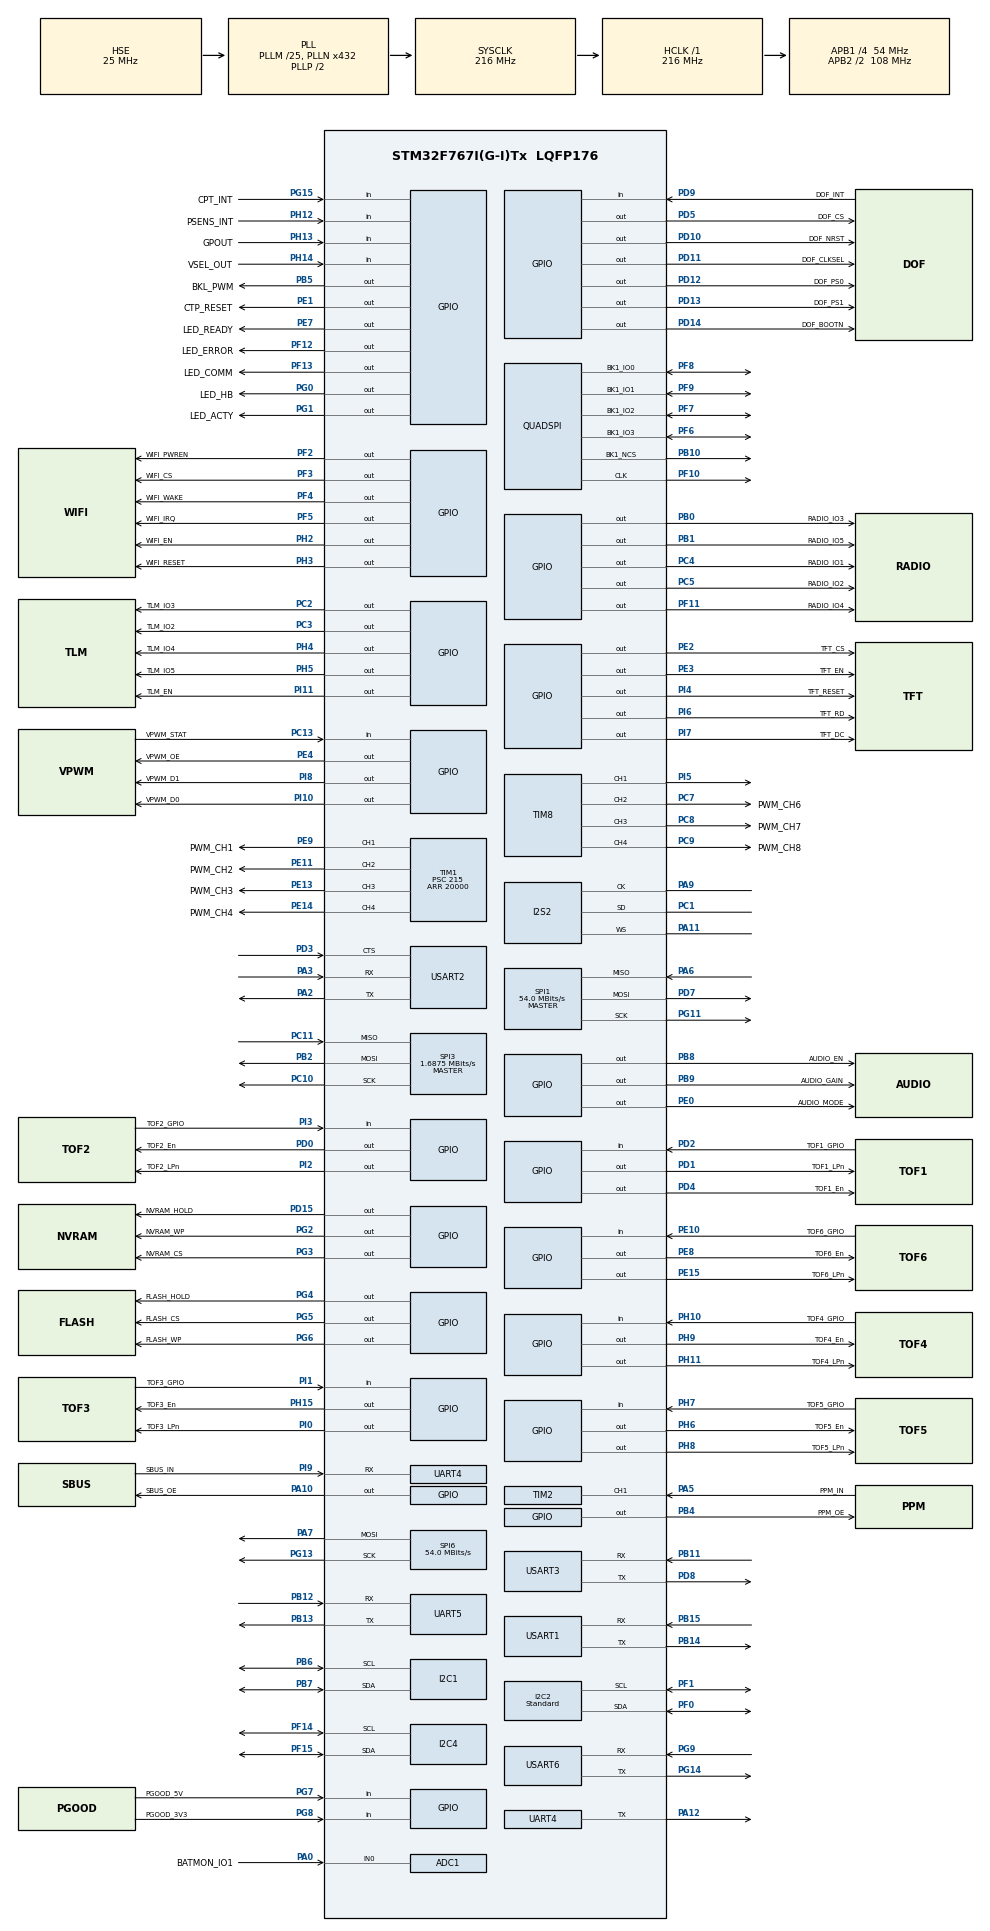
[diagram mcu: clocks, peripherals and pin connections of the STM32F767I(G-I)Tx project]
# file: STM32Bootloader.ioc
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ADC1.Channel-0\#ChannelRegularConversion=ADC_CHANNEL_0
ADC1.NbrOfConversionFlag=1
ADC1.Rank-0\#ChannelRegularConversion=1
ADC1.SamplingTime-0\#ChannelRegularConversion=ADC_SAMPLETIME_3CYCLES
ADC1.master=1
CORTEX_M7.AccessPermission-Cortex_Memory_Protection_Unit_Region0_Settings=MPU_REGION_FULL_ACCESS
CORTEX_M7.AccessPermission-Cortex_Memory_Protection_Unit_Region2_Settings=MPU_REGION_FULL_ACCESS
CORTEX_M7.AccessPermission-Cortex_Memory_Protection_Unit_Region3_Settings=MPU_REGION_FULL_ACCESS
CORTEX_M7.AccessPermission_S-Cortex_Memory_Protection_Unit_Region2_Settings_S=MPU_REGION_FULL_ACCESS
CORTEX_M7.AccessPermission_S-Cortex_Memory_Protection_Unit_Region3_Settings_S=MPU_REGION_FULL_ACCESS
CORTEX_M7.BaseAddress-Cortex_Memory_Protection_Unit_Region0_Settings=0x20000000
CORTEX_M7.BaseAddress-Cortex_Memory_Protection_Unit_Region1_Settings=0x90000000
CORTEX_M7.BaseAddress-Cortex_Memory_Protection_Unit_Region2_Settings=0x90000000
CORTEX_M7.BaseAddress-Cortex_Memory_Protection_Unit_Region3_Settings=0x90000000
CORTEX_M7.BaseAddress_S-Cortex_Memory_Protection_Unit_Region1_Settings_S=0x90000000
CORTEX_M7.BaseAddress_S-Cortex_Memory_Protection_Unit_Region2_Settings_S=0x90000000
CORTEX_M7.BaseAddress_S-Cortex_Memory_Protection_Unit_Region3_Settings_S=0x90000000
CORTEX_M7.BaseAddress_Spec=0x20000000
CORTEX_M7.CPU_DCache=Enabled
CORTEX_M7.CPU_ICache=Enabled
CORTEX_M7.DisableExec-Cortex_Memory_Protection_Unit_Region0_Settings=MPU_INSTRUCTION_ACCESS_DISABLE
CORTEX_M7.DisableExec-Cortex_Memory_Protection_Unit_Region1_Settings=MPU_INSTRUCTION_ACCESS_DISABLE
CORTEX_M7.DisableExec_S-Cortex_Memory_Protection_Unit_Region1_Settings_S=MPU_INSTRUCTION_ACCESS_DISABLE
CORTEX_M7.Enable-Cortex_Memory_Protection_Unit_Region0_Settings=MPU_REGION_ENABLE
CORTEX_M7.Enable-Cortex_Memory_Protection_Unit_Region1_Settings=MPU_REGION_ENABLE
CORTEX_M7.Enable-Cortex_Memory_Protection_Unit_Region2_Settings=MPU_REGION_ENABLE
CORTEX_M7.Enable-Cortex_Memory_Protection_Unit_Region3_Settings=MPU_REGION_ENABLE
CORTEX_M7.Enable_S-Cortex_Memory_Protection_Unit_Region1_Settings_S=MPU_REGION_ENABLE
CORTEX_M7.Enable_S-Cortex_Memory_Protection_Unit_Region2_Settings_S=MPU_REGION_ENABLE
CORTEX_M7.Enable_S-Cortex_Memory_Protection_Unit_Region3_Settings_S=MPU_REGION_ENABLE
CORTEX_M7.IsBufferable-Cortex_Memory_Protection_Unit_Region3_Settings=MPU_ACCESS_BUFFERABLE
CORTEX_M7.IsBufferable_S-Cortex_Memory_Protection_Unit_Region3_Settings_S=MPU_ACCESS_BUFFERABLE
CORTEX_M7.IsCacheable-Cortex_Memory_Protection_Unit_Region2_Settings=MPU_ACCESS_CACHEABLE
CORTEX_M7.IsCacheable-Cortex_Memory_Protection_Unit_Region3_Settings=MPU_ACCESS_CACHEABLE
CORTEX_M7.IsCacheable_S-Cortex_Memory_Protection_Unit_Region2_Settings_S=MPU_ACCESS_CACHEABLE
CORTEX_M7.IsCacheable_S-Cortex_Memory_Protection_Unit_Region3_Settings_S=MPU_ACCESS_CACHEABLE
CORTEX_M7.IsShareable-Cortex_Memory_Protection_Unit_Region0_Settings=MPU_ACCESS_SHAREABLE
CORTEX_M7.MPU_Control=MPU_PRIVILEGED_DEFAULT
CORTEX_M7.PREFETCH_ENABLE=1
CORTEX_M7.Size-Cortex_Memory_Protection_Unit_Region0_Settings=MPU_REGION_SIZE_512MB
CORTEX_M7.Size-Cortex_Memory_Protection_Unit_Region1_Settings=MPU_REGION_SIZE_512MB
CORTEX_M7.Size-Cortex_Memory_Protection_Unit_Region2_Settings=MPU_REGION_SIZE_16MB
CORTEX_M7.Size-Cortex_Memory_Protection_Unit_Region3_Settings=MPU_REGION_SIZE_1MB
CORTEX_M7.Size_S-Cortex_Memory_Protection_Unit_Region1_Settings_S=MPU_REGION_SIZE_512MB
CORTEX_M7.Size_S-Cortex_Memory_Protection_Unit_Region2_Settings_S=MPU_REGION_SIZE_16MB
CORTEX_M7.Size_S-Cortex_Memory_Protection_Unit_Region3_Settings_S=MPU_REGION_SIZE_1MB
CORTEX_M7.Size_Spec=MPU_REGION_SIZE_512KB
CORTEX_M7.SubRegionDisable_Spec=0x0
CORTEX_M7.TypeExtField-Cortex_Memory_Protection_Unit_Region0_Settings=MPU_TEX_LEVEL1
CORTEX_M7.default_mode_Activation=0
Dma.QUADSPI.0.Direction=DMA_PERIPH_TO_MEMORY
Dma.QUADSPI.0.FIFOMode=DMA_FIFOMODE_DISABLE
Dma.QUADSPI.0.Instance=DMA2_Stream2
Dma.QUADSPI.0.MemDataAlignment=DMA_MDATAALIGN_BYTE
Dma.QUADSPI.0.MemInc=DMA_MINC_ENABLE
Dma.QUADSPI.0.Mode=DMA_NORMAL
Dma.QUADSPI.0.PeriphDataAlignment=DMA_PDATAALIGN_BYTE
Dma.QUADSPI.0.PeriphInc=DMA_PINC_DISABLE
Dma.QUADSPI.0.Priority=DMA_PRIORITY_LOW
Dma.Request0=QUADSPI
Dma.Request1=USART1_RX
Dma.Request2=USART1_TX
Dma.USART1_RX.1.Direction=DMA_PERIPH_TO_MEMORY
Dma.USART1_RX.1.FIFOMode=DMA_FIFOMODE_DISABLE
Dma.USART1_RX.1.Instance=DMA2_Stream5
Dma.USART1_RX.1.MemDataAlignment=DMA_MDATAALIGN_BYTE
Dma.USART1_RX.1.MemInc=DMA_MINC_ENABLE
Dma.USART1_RX.1.Mode=DMA_CIRCULAR
Dma.USART1_RX.1.PeriphDataAlignment=DMA_PDATAALIGN_BYTE
Dma.USART1_RX.1.PeriphInc=DMA_PINC_DISABLE
Dma.USART1_RX.1.Priority=DMA_PRIORITY_LOW
Dma.USART1_TX.2.Direction=DMA_MEMORY_TO_PERIPH
Dma.USART1_TX.2.FIFOMode=DMA_FIFOMODE_DISABLE
Dma.USART1_TX.2.Instance=DMA2_Stream7
Dma.USART1_TX.2.MemDataAlignment=DMA_MDATAALIGN_BYTE
Dma.USART1_TX.2.MemInc=DMA_MINC_ENABLE
Dma.USART1_TX.2.Mode=DMA_NORMAL
Dma.USART1_TX.2.PeriphDataAlignment=DMA_PDATAALIGN_BYTE
Dma.USART1_TX.2.PeriphInc=DMA_PINC_DISABLE
Dma.USART1_TX.2.Priority=DMA_PRIORITY_LOW
FREERTOS.Tasks01=defaultTask,24,128,StartDefaultTask,Default,NULL,Dynamic,NULL,NULL
FREERTOS.configTOTAL_HEAP_SIZE=60000
I2C1.Timing=0x20404768
I2C2.I2C_Speed_Mode=I2C_Standard
I2C2.Timing=0x20404768
I2C4.Timing=0x20404768
I2S2.ErrorAudioFreq=0.0 %
I2S2.FullDuplexMode=I2S_FULLDUPLEXMODE_DISABLE
I2S2.Instance=SPI$Index
I2S2.RealAudioFreq=8.0 KHz
I2S2.VirtualMode=I2S_MODE_MASTER
Mcu.Family=STM32F7
Mcu.Name=STM32F767I(G-I)Tx
Mcu.Package=LQFP176
NVIC.DMA2_Stream2_IRQn=true\:5\:0\:false\:false\:true\:true\:false\:true\:true
NVIC.DMA2_Stream5_IRQn=true\:5\:0\:false\:false\:true\:false\:false\:true\:true
NVIC.DMA2_Stream7_IRQn=true\:5\:0\:false\:false\:true\:true\:false\:true\:true
NVIC.PriorityGroup=NVIC_PRIORITYGROUP_4
NVIC.QUADSPI_IRQn=true\:5\:0\:false\:false\:true\:true\:true\:true\:true
NVIC.TIM6_DAC_IRQn=true\:15\:0\:false\:false\:true\:false\:false\:true\:true
NVIC.TimeBase=TIM6_DAC_IRQn
NVIC.TimeBaseIP=TIM6
NVIC.USART1_IRQn=true\:5\:0\:false\:false\:true\:true\:true\:true\:true
PA0/WKUP.GPIO_Label=BATMON_IO1
PA0/WKUP.Signal=ADCx_IN0
PA10.GPIO_Label=SBUS_OE
PA10.Signal=GPIO_Output
PA11.Mode=Half_Duplex_Master
PA11.Signal=I2S2_WS
PA12.Mode=Asynchronous
PA12.Signal=UART4_TX
PA2.Mode=Asynchronous
PA2.Signal=USART2_TX
PA3.Mode=Asynchronous
PA3.Signal=USART2_RX
PA5.GPIO_Label=PPM_IN
PA5.Signal=S_TIM2_CH1_ETR
PA6.Mode=Full_Duplex_Master
PA6.Signal=SPI1_MISO
PA7.Mode=TX_Only_Simplex_Unidirect_Master
PA7.Signal=SPI6_MOSI
PA9.Mode=Half_Duplex_Master
PA9.Signal=I2S2_CK
PB0.GPIO_Label=RADIO_IO3
PB0.Signal=GPIO_Output
PB1.GPIO_Label=RADIO_IO5
PB1.Signal=GPIO_Output
PB10.GPIO_PuPd=GPIO_PULLDOWN
PB10.Mode=Single Bank 1
PB10.Signal=QUADSPI_BK1_NCS
PB11.Mode=Asynchronous
PB11.Signal=USART3_RX
PB12.Mode=Asynchronous
PB12.Signal=UART5_RX
PB13.Mode=Asynchronous
PB13.Signal=UART5_TX
PB14.Mode=Asynchronous
PB14.Signal=USART1_TX
PB15.Mode=Asynchronous
PB15.Signal=USART1_RX
PB2.Mode=Full_Duplex_Master
PB2.Signal=SPI3_MOSI
PB4.GPIO_Label=PPM_OE
PB4.Signal=GPIO_Output
PB5.GPIO_Label=BKL_PWM
PB5.Signal=GPIO_Output
PB6.Mode=I2C
PB6.Signal=I2C1_SCL
PB7.Mode=I2C
PB7.Signal=I2C1_SDA
PB8.GPIO_Label=AUDIO_EN
PB8.Signal=GPIO_Output
PB9.GPIO_Label=AUDIO_GAIN
PB9.Signal=GPIO_Output
PC1.Mode=Half_Duplex_Master
PC1.Signal=I2S2_SD
PC10.Mode=Full_Duplex_Master
PC10.Signal=SPI3_SCK
PC11.Mode=Full_Duplex_Master
PC11.Signal=SPI3_MISO
PC13.GPIO_Label=VPWM_STAT
PC13.Signal=GPIO_Input
PC14/OSC32_IN.Mode=LSE-External-Oscillator
PC14/OSC32_IN.Signal=RCC_OSC32_IN
PC15/OSC32_OUT.Mode=LSE-External-Oscillator
PC15/OSC32_OUT.Signal=RCC_OSC32_OUT
PC2.GPIO_Label=TLM_IO3
PC2.Signal=GPIO_Output
PC3.GPIO_Label=TLM_IO2
PC3.Signal=GPIO_Output
PC4.GPIO_Label=RADIO_IO1
PC4.Signal=GPIO_Output
PC5.GPIO_Label=RADIO_IO2
PC5.Signal=GPIO_Output
PC7.GPIO_Label=PWM_CH6
PC7.Signal=S_TIM8_CH2
PC8.GPIO_Label=PWM_CH7
PC8.Signal=S_TIM8_CH3
PC9.GPIO_Label=PWM_CH8
PC9.Signal=S_TIM8_CH4
PD0.GPIO_Label=TOF2_En
PD0.Signal=GPIO_Output
PD1.GPIO_Label=TOF1_LPn
PD1.Signal=GPIO_Output
PD10.GPIO_Label=DOF_NRST
PD10.GPIO_PuPd=GPIO_PULLUP
PD10.PinState=GPIO_PIN_SET
PD10.Signal=GPIO_Output
PD11.GPIO_Label=DOF_CLKSEL
PD11.GPIO_PuPd=GPIO_PULLDOWN
PD11.PinState=GPIO_PIN_RESET
PD11.Signal=GPIO_Output
PD12.GPIO_Label=DOF_PS0
PD12.GPIO_PuPd=GPIO_PULLUP
PD12.PinState=GPIO_PIN_SET
PD12.Signal=GPIO_Output
PD13.GPIO_Label=DOF_PS1
PD13.GPIO_PuPd=GPIO_PULLUP
PD13.PinState=GPIO_PIN_SET
PD13.Signal=GPIO_Output
PD14.GPIO_Label=DOF_BOOTN
PD14.GPIO_PuPd=GPIO_PULLUP
PD14.PinState=GPIO_PIN_SET
PD14.Signal=GPIO_Output
PD15.GPIO_Label=NVRAM_HOLD
PD15.GPIO_PuPd=GPIO_NOPULL
PD15.Signal=GPIO_Output
PD2.GPIO_Label=TOF1_GPIO
PD2.Signal=GPIO_Input
PD3.Mode=CTS_Only
PD3.Signal=USART2_CTS
PD4.GPIO_Label=TOF1_En 
PD4.Signal=GPIO_Output
PD5.GPIO_Label=DOF_CS
PD5.GPIO_PuPd=GPIO_PULLUP
PD5.PinState=GPIO_PIN_SET
PD5.Signal=GPIO_Output
PD7.Mode=Full_Duplex_Master
PD7.Signal=SPI1_MOSI
PD8.Mode=Asynchronous
PD8.Signal=USART3_TX
PD9.GPIO_Label=DOF_INT
PD9.GPIO_PuPd=GPIO_PULLUP
PD9.Signal=GPIO_Input
PE0.GPIO_Label=AUDIO_MODE
PE0.Signal=GPIO_Output
PE1.GPIO_Label=CTP_RESET
PE1.Signal=GPIO_Output
PE10.GPIO_Label=TOF6_GPIO
PE10.Signal=GPIO_Input
PE11.GPIO_Label=PWM_CH2
PE11.Signal=S_TIM1_CH2
PE13.GPIO_Label=PWM_CH3
PE13.Signal=S_TIM1_CH3
PE14.GPIO_Label=PWM_CH4
PE14.Signal=S_TIM1_CH4
PE15.GPIO_Label=TOF6_LPn
PE15.Signal=GPIO_Output
PE2.GPIO_Label=TFT_CS
PE2.GPIO_PuPd=GPIO_PULLUP
PE2.Signal=GPIO_Output
PE3.GPIO_Label=TFT_EN
PE3.Signal=GPIO_Output
PE4.GPIO_Label=VPWM_OE
PE4.Signal=GPIO_Output
PE7.GPIO_Label=LED_READY
PE7.PinState=GPIO_PIN_SET
PE7.Signal=GPIO_Output
PE8.GPIO_Label=TOF6_En
PE8.Signal=GPIO_Output
PE9.GPIO_Label=PWM_CH1
PE9.Signal=S_TIM1_CH1
PF0.GPIO_Pu=GPIO_PULLUP
PF0.Mode=I2C
PF0.Signal=I2C2_SDA
PF1.GPIO_Pu=GPIO_PULLUP
PF1.Mode=I2C
PF1.Signal=I2C2_SCL
PF10.GPIO_PuPd=GPIO_NOPULL
PF10.Mode=Single Bank 1
PF10.Signal=QUADSPI_CLK
PF11.GPIO_Label=RADIO_IO4
PF11.Signal=GPIO_Output
PF12.GPIO_Label=LED_ERROR
PF12.PinState=GPIO_PIN_SET
PF12.Signal=GPIO_Output
PF13.GPIO_Label=LED_COMM
PF13.PinState=GPIO_PIN_SET
PF13.Signal=GPIO_Output
PF14.Mode=I2C
PF14.Signal=I2C4_SCL
PF15.Mode=I2C
PF15.Signal=I2C4_SDA
PF2.GPIO_Label=WIFI_PWREN
PF2.Signal=GPIO_Output
PF3.GPIO_Label=WIFI_CS
PF3.GPIO_PuPd=GPIO_PULLUP
PF3.Signal=GPIO_Output
PF4.GPIO_Label=WIFI_WAKE
PF4.Signal=GPIO_Output
PF5.GPIO_Label=WIFI_IRQ
PF5.Signal=GPIO_Output
PF6.Mode=Single Bank 1
PF6.Signal=QUADSPI_BK1_IO3
PF7.Mode=Single Bank 1
PF7.Signal=QUADSPI_BK1_IO2
PF8.Mode=Single Bank 1
PF8.Signal=QUADSPI_BK1_IO0
PF9.Mode=Single Bank 1
PF9.Signal=QUADSPI_BK1_IO1
PG0.GPIO_Label=LED_HB
PG0.PinState=GPIO_PIN_SET
PG0.Signal=GPIO_Output
PG1.GPIO_Label=LED_ACTY
PG1.PinState=GPIO_PIN_SET
PG1.Signal=GPIO_Output
PG11.Mode=Full_Duplex_Master
PG11.Signal=SPI1_SCK
PG13.Mode=TX_Only_Simplex_Unidirect_Master
PG13.Signal=SPI6_SCK
PG14.Mode=Asynchronous
PG14.Signal=USART6_TX
PG15.GPIO_Label=CPT_INT
PG15.Signal=GPIO_Input
PG2.GPIO_Label=NVRAM_WP
PG2.GPIO_PuPd=GPIO_NOPULL
PG2.Signal=GPIO_Output
PG3.GPIO_Label=NVRAM_CS
PG3.GPIO_PuPd=GPIO_PULLUP
PG3.Signal=GPIO_Output
PG4.GPIO_Label=FLASH_HOLD
PG4.GPIO_PuPd=GPIO_PULLUP
PG4.Signal=GPIO_Output
PG5.GPIO_Label=FLASH_CS
PG5.GPIO_PuPd=GPIO_PULLUP
PG5.Signal=GPIO_Output
PG6.GPIO_Label=FLASH_WP
PG6.GPIO_PuPd=GPIO_PULLUP
PG6.Signal=GPIO_Output
PG7.GPIO_Label=PGOOD_5V
PG7.Signal=GPIO_Input
PG8.GPIO_Label=PGOOD_3V3
PG8.Signal=GPIO_Input
PG9.Mode=Asynchronous
PG9.Signal=USART6_RX
PH0/OSC_IN.Mode=HSE-External-Oscillator
PH0/OSC_IN.Signal=RCC_OSC_IN
PH1/OSC_OUT.Mode=HSE-External-Oscillator
PH1/OSC_OUT.Signal=RCC_OSC_OUT
PH10.GPIO_Label=TOF4_GPIO
PH10.Signal=GPIO_Input
PH11.GPIO_Label=TOF4_LPn
PH11.Signal=GPIO_Output
PH12.GPIO_Label=PSENS_INT
PH12.Signal=GPIO_Input
PH13.GPIO_Label=GPOUT
PH13.Signal=GPIO_Input
PH14.GPIO_Label=VSEL_OUT
PH14.Signal=GPIO_Input
PH15.GPIO_Label=TOF3_En
PH15.Signal=GPIO_Output
PH2.GPIO_Label=WIFI_EN
PH2.Signal=GPIO_Output
PH3.GPIO_Label=WIFI_RESET
PH3.Signal=GPIO_Output
PH4.GPIO_Label=TLM_IO4
PH4.Signal=GPIO_Output
PH5.GPIO_Label=TLM_IO5
PH5.Signal=GPIO_Output
PH6.GPIO_Label=TOF5_En
PH6.Signal=GPIO_Output
PH7.GPIO_Label=TOF5_GPIO
PH7.Signal=GPIO_Input
PH8.GPIO_Label=TOF5_LPn
PH8.Signal=GPIO_Output
PH9.GPIO_Label=TOF4_En
PH9.Signal=GPIO_Output
PI0.GPIO_Label=TOF3_LPn
PI0.Signal=GPIO_Output
PI1.GPIO_Label=TOF3_GPIO
PI1.Signal=GPIO_Input
PI10.GPIO_Label=VPWM_D0
PI10.Signal=GPIO_Output
PI11.GPIO_Label=TLM_EN
PI11.Signal=GPIO_Output
PI2.GPIO_Label=TOF2_LPn
PI2.Signal=GPIO_Output
PI3.GPIO_Label=TOF2_GPIO
PI3.Signal=GPIO_Input
PI4.GPIO_Label=TFT_RESET
PI4.Signal=GPIO_Output
PI5.Signal=S_TIM8_CH1
PI6.GPIO_Label=TFT_RD
PI6.Signal=GPIO_Output
PI7.GPIO_Label=TFT_DC
PI7.Signal=GPIO_Output
PI8.GPIO_Label=VPWM_D1
PI8.PinState=GPIO_PIN_SET
PI8.Signal=GPIO_Output
PI9.GPIO_Label=SBUS_IN
PI9.Mode=Asynchronous
PI9.Signal=UART4_RX
ProjectManager.HeapSize=0x200
ProjectManager.StackSize=0x400
ProjectManager.TargetToolchain=CMake
QUADSPI.ChipSelectHighTime=QSPI_CS_HIGH_TIME_6_CYCLE
QUADSPI.ClockMode=QSPI_CLOCK_MODE_0
QUADSPI.ClockPrescaler=1
QUADSPI.DeviceType=SPI_DEVICE_FLASH
QUADSPI.FifoThreshold=4
QUADSPI.FlashSize=23
QUADSPI.SampleShifting=QSPI_SAMPLE_SHIFTING_HALFCYCLE
RCC.AHBFreq_Value=216000000
RCC.APB1CLKDivider=RCC_HCLK_DIV4
RCC.APB1Freq_Value=54000000
RCC.APB1TimFreq_Value=108000000
RCC.APB2CLKDivider=RCC_HCLK_DIV2
RCC.APB2Freq_Value=108000000
RCC.APB2TimFreq_Value=216000000
RCC.CortexFreq_Value=216000000
RCC.HCLKFreq_Value=216000000
RCC.HSE_VALUE=25000000
RCC.HSI_VALUE=16000000
RCC.PLLM=25
RCC.PLLN=432
RCC.PLLQ=9
RCC.PLLSourceVirtual=RCC_PLLSOURCE_HSE
RCC.SYSCLKFreq_VALUE=216000000
RCC.SYSCLKSource=RCC_SYSCLKSOURCE_PLLCLK
RCC.USBFreq_Value=48000000
RCC.VCOOutputFreq_Value=432000000
SH.ADCx_IN0.0=ADC1_IN0,IN0
SH.S_TIM1_CH1.0=TIM1_CH1,PWM Generation1 CH1
SH.S_TIM1_CH2.0=TIM1_CH2,PWM Generation2 CH2
SH.S_TIM1_CH3.0=TIM1_CH3,PWM Generation3 CH3
SH.S_TIM1_CH4.0=TIM1_CH4,PWM Generation4 CH4
SH.S_TIM2_CH1_ETR.0=TIM2_CH1,Input_Capture1_from_TI1
SH.S_TIM8_CH1.0=TIM8_CH1,PWM Generation1 CH1
SH.S_TIM8_CH2.0=TIM8_CH2,PWM Generation2 CH2
SH.S_TIM8_CH3.0=TIM8_CH3,Output Compare3 CH3
SH.S_TIM8_CH4.0=TIM8_CH4,PWM Generation4 CH4
SPI1.CalculateBaudRate=54.0 MBits/s
SPI1.DataSize=SPI_DATASIZE_8BIT
SPI1.Direction=SPI_DIRECTION_2LINES
SPI1.Mode=SPI_MODE_MASTER
SPI1.VirtualType=VM_MASTER
SPI3.BaudRatePrescaler=SPI_BAUDRATEPRESCALER_32
SPI3.CLKPhase=SPI_PHASE_2EDGE
SPI3.CLKPolarity=SPI_POLARITY_HIGH
SPI3.CalculateBaudRate=1.6875 MBits/s
SPI3.DataSize=SPI_DATASIZE_8BIT
SPI3.Direction=SPI_DIRECTION_2LINES
SPI3.Mode=SPI_MODE_MASTER
SPI3.VirtualType=VM_MASTER
SPI6.BaudRatePrescaler=SPI_BAUDRATEPRESCALER_2
SPI6.CalculateBaudRate=54.0 MBits/s
SPI6.DataSize=SPI_DATASIZE_8BIT
SPI6.Direction=SPI_DIRECTION_2LINES
SPI6.Mode=SPI_MODE_MASTER
SPI6.VirtualType=VM_MASTER
STMicroelectronics.X-CUBE-TOUCHGFX.4.25.0.ApplicationCcGraphicsJjApplication=TouchGFXOoGenerator
STMicroelectronics.X-CUBE-TOUCHGFX.4.25.0.tgfx_address1=0x90C00000
STMicroelectronics.X-CUBE-TOUCHGFX.4.25.0.tgfx_custom_height=320
STMicroelectronics.X-CUBE-TOUCHGFX.4.25.0.tgfx_custom_width=170
STMicroelectronics.X-CUBE-TOUCHGFX.4.25.0.tgfx_location=Allocate
STMicroelectronics.X-CUBE-TOUCHGFX.4.25.0_IsPackSelfContextualization=true
TIM1.Channel-PWM\ Generation1\ CH1=TIM_CHANNEL_1
TIM1.Channel-PWM\ Generation2\ CH2=TIM_CHANNEL_2
TIM1.Channel-PWM\ Generation3\ CH3=TIM_CHANNEL_3
TIM1.Channel-PWM\ Generation4\ CH4=TIM_CHANNEL_4
TIM1.Period=20000
TIM1.Prescaler=215
TIM1.Pulse-PWM\ Generation1\ CH1=1500
TIM2.Channel-Input_Capture1_from_TI1=TIM_CHANNEL_1
TIM8.Channel-Output\ Compare3\ CH3=TIM_CHANNEL_3
TIM8.Channel-PWM\ Generation1\ CH1=TIM_CHANNEL_1
TIM8.Channel-PWM\ Generation2\ CH2=TIM_CHANNEL_2
TIM8.Channel-PWM\ Generation4\ CH4=TIM_CHANNEL_4
UART4.Mode=MODE_TX_RX
USART1.VirtualMode-Asynchronous=VM_ASYNC
USART2.VirtualMode-Asynchronous=VM_ASYNC
USART3.VirtualMode-Asynchronous=VM_ASYNC
USART6.VirtualMode-Asynchronous=VM_ASYNC
VP_CRC_VS_CRC.Mode=CRC_Activate
VP_FREERTOS_VS_CMSIS_V2.Mode=CMSIS_V2
VP_RNG_VS_RNG.Mode=RNG_Activate
VP_STMicroelectronics.X-CUBE-TOUCHGFX_VS_GraphicsJjApplication_4.25.0.Mode=GraphicsJjApplication
VP_SYS_VS_tim6.Mode=TIM6
VP_TIM1_VS_ClockSourceINT.Mode=Internal
VP_TIM2_VS_ClockSourceINT.Mode=Internal
VP_TIM3_VS_ClockSourceINT.Mode=Internal
VP_TIM8_VS_ClockSourceINT.Mode=Internal
board=custom

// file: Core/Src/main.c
/* USER CODE BEGIN Header */
/**
  ******************************************************************************
  * @file           : main.c
  * @brief          : Main program body
  ******************************************************************************
  * @attention
  *
  * Copyright (c) 2025 STMicroelectronics.
  * All rights reserved.
  *
  * This software is licensed under terms that can be found in the LICENSE file
  * in the root directory of this software component.
  * If no LICENSE file comes with this software, it is provided AS-IS.
  *
  ******************************************************************************
  */
/* USER CODE END Header */
#include "main.h"
#include "cmsis_os.h"
#include "app_touchgfx.h"

/* USER CODE BEGIN Includes */
#ifdef __cplusplus
extern "C" {
#endif
#include "app.h" // your C++ main
#include "boot_entry.h"
#include "boot_defs.h"
#ifdef __cplusplus
}
#endif

extern void main_cpp(void);
extern void check_and_jump_to_bootloader(void);
#include "log.h"

/* USER CODE END Includes */

ADC_HandleTypeDef hadc1;

CRC_HandleTypeDef hcrc;

I2C_HandleTypeDef hi2c1;
I2C_HandleTypeDef hi2c2;
I2C_HandleTypeDef hi2c4;

I2S_HandleTypeDef hi2s2;

QSPI_HandleTypeDef hqspi;
DMA_HandleTypeDef hdma_quadspi;

RNG_HandleTypeDef hrng;

SPI_HandleTypeDef hspi1;
SPI_HandleTypeDef hspi3;
SPI_HandleTypeDef hspi6;

TIM_HandleTypeDef htim1;
TIM_HandleTypeDef htim2;
TIM_HandleTypeDef htim3;
TIM_HandleTypeDef htim8;

UART_HandleTypeDef huart4;
UART_HandleTypeDef huart5;
UART_HandleTypeDef huart1;
UART_HandleTypeDef huart2;
UART_HandleTypeDef huart3;
UART_HandleTypeDef huart6;
DMA_HandleTypeDef hdma_usart1_rx;
DMA_HandleTypeDef hdma_usart1_tx;

/* Definitions for defaultTask */
osThreadId_t defaultTaskHandle;
const osThreadAttr_t defaultTask_attributes = {
  .name = "defaultTask",
  .stack_size = 128 * 4,
  .priority = (osPriority_t) osPriorityNormal,
};
/* USER CODE BEGIN PV */
int _write(int file, char*ptr, int len)
{
	HAL_UART_Transmit(&huart1, (uint8_t*)ptr, len, HAL_MAX_DELAY);
	return len;

}
/* USER CODE END PV */

void SystemClock_Config(void);
static void MPU_Config(void);
static void MX_GPIO_Init(void);
static void MX_DMA_Init(void);
static void MX_ADC1_Init(void);
static void MX_CRC_Init(void);
static void MX_I2C1_Init(void);
static void MX_I2C2_Init(void);
static void MX_I2C4_Init(void);
static void MX_I2S2_Init(void);
static void MX_QUADSPI_Init(void);
static void MX_RNG_Init(void);
static void MX_SPI1_Init(void);
static void MX_SPI6_Init(void);
static void MX_TIM1_Init(void);
static void MX_TIM2_Init(void);
static void MX_TIM3_Init(void);
static void MX_TIM8_Init(void);
static void MX_UART4_Init(void);
static void MX_UART5_Init(void);
static void MX_USART1_UART_Init(void);
static void MX_USART2_UART_Init(void);
static void MX_USART3_UART_Init(void);
static void MX_USART6_UART_Init(void);
static void MX_SPI3_Init(void);
void StartDefaultTask(void *argument);

int main(void)
{

  /* MPU Configuration--------------------------------------------------------*/
  MPU_Config();

  /* Enable the CPU Cache */

  /* Enable I-Cache---------------------------------------------------------*/
  SCB_EnableICache();

  /* Enable D-Cache---------------------------------------------------------*/
  SCB_EnableDCache();

  /* MCU Configuration--------------------------------------------------------*/

  /* Reset of all peripherals, Initializes the Flash interface and the Systick. */
  HAL_Init();

  /* USER CODE BEGIN Init */
  SystemClock_Config();
  MX_GPIO_Init();
  //MX_USART1_UART_Init();

  #if BOOT_FUSE_BACKEND_SELECTED == BOOT_FUSE_BACKEND_SPI_FLASH
  MX_SPI1_Init();
  #elif BOOT_FUSE_BACKEND_SELECTED == BOOT_FUSE_BACKEND_QSPI_FLASH
   MX_QUADSPI_Init();
   //MX_DMA_Init();
  #elif BOOT_FUSE_BACKEND_SELECTED == BOOT_FUSE_BACKEND_EEPROM
  #elif
  #endif

  check_and_jump_to_bootloader();

#if BOOT_FUSE_BACKEND_SELECTED == BOOT_FUSE_BACKEND_SPI_FLASH
 HAL_SPI_DeInit(&hspi);
#elif BOOT_FUSE_BACKEND_SELECTED == BOOT_FUSE_BACKEND_QSPI_FLASH
 HAL_QSPI_DeInit(&hqspi);
  //HAL_DMA_DeInit(&hdma_quadspi);
#elif BOOT_FUSE_BACKEND_SELECTED == BOOT_FUSE_BACKEND_EEPROM
#elif
#endif
//HAL_DeInit();
  /* USER CODE END Init */

  /* Configure the system clock */
  SystemClock_Config();

  /* Initialize all configured peripherals */
  MX_GPIO_Init();
  MX_DMA_Init();
  MX_ADC1_Init();
  MX_CRC_Init();
  MX_I2C1_Init();
  MX_I2C2_Init();
  MX_I2C4_Init();
  MX_I2S2_Init();
  MX_QUADSPI_Init();
  MX_RNG_Init();
  MX_SPI1_Init();
  MX_SPI6_Init();
  MX_TIM1_Init();
  MX_TIM2_Init();
  MX_TIM3_Init();
  MX_TIM8_Init();
  MX_UART4_Init();
  MX_UART5_Init();
  MX_USART1_UART_Init();
  MX_USART2_UART_Init();
  MX_USART3_UART_Init();
  MX_USART6_UART_Init();
  MX_SPI3_Init();
  MX_TouchGFX_Init();
  /* Call PreOsInit function */
  MX_TouchGFX_PreOSInit();
  /* USER CODE BEGIN 2 */
  bootloader_app(); // jump to C++ app
  while(1)
  {

  }
  /* USER CODE END 2 */

  /* Init scheduler */
  osKernelInitialize();

  /* Create the thread(s) */
  /* creation of defaultTask */
  defaultTaskHandle = osThreadNew(StartDefaultTask, NULL, &defaultTask_attributes);

  /* Start scheduler */
  osKernelStart();

  /* We should never get here as control is now taken by the scheduler */

  /* Infinite loop */
  while (1)
  {

  }
}

void SystemClock_Config(void)
{
  RCC_OscInitTypeDef RCC_OscInitStruct = {0};
  RCC_ClkInitTypeDef RCC_ClkInitStruct = {0};

  /** Configure LSE Drive Capability
  */
  HAL_PWR_EnableBkUpAccess();

  /** Configure the main internal regulator output voltage
  */
  __HAL_RCC_PWR_CLK_ENABLE();
  __HAL_PWR_VOLTAGESCALING_CONFIG(PWR_REGULATOR_VOLTAGE_SCALE1);

  /** Initializes the RCC Oscillators according to the specified parameters
  * in the RCC_OscInitTypeDef structure.
  */
  RCC_OscInitStruct.OscillatorType = RCC_OSCILLATORTYPE_HSE;
  RCC_OscInitStruct.HSEState = RCC_HSE_ON;
  RCC_OscInitStruct.PLL.PLLState = RCC_PLL_ON;
  RCC_OscInitStruct.PLL.PLLSource = RCC_PLLSOURCE_HSE;
  RCC_OscInitStruct.PLL.PLLM = 25;
  RCC_OscInitStruct.PLL.PLLN = 432;
  RCC_OscInitStruct.PLL.PLLP = RCC_PLLP_DIV2;
  RCC_OscInitStruct.PLL.PLLQ = 9;
  RCC_OscInitStruct.PLL.PLLR = 2;
  if (HAL_RCC_OscConfig(&RCC_OscInitStruct) != HAL_OK)
  {
    Error_Handler();
  }

  /** Activate the Over-Drive mode
  */
  if (HAL_PWREx_EnableOverDrive() != HAL_OK)
  {
    Error_Handler();
  }

  /** Initializes the CPU, AHB and APB buses clocks
  */
  RCC_ClkInitStruct.ClockType = RCC_CLOCKTYPE_HCLK|RCC_CLOCKTYPE_SYSCLK
                              |RCC_CLOCKTYPE_PCLK1|RCC_CLOCKTYPE_PCLK2;
  RCC_ClkInitStruct.SYSCLKSource = RCC_SYSCLKSOURCE_PLLCLK;
  RCC_ClkInitStruct.AHBCLKDivider = RCC_SYSCLK_DIV1;
  RCC_ClkInitStruct.APB1CLKDivider = RCC_HCLK_DIV4;
  RCC_ClkInitStruct.APB2CLKDivider = RCC_HCLK_DIV2;

  if (HAL_RCC_ClockConfig(&RCC_ClkInitStruct, FLASH_LATENCY_7) != HAL_OK)
  {
    Error_Handler();
  }
}

static void MX_ADC1_Init(void)
{

  ADC_ChannelConfTypeDef sConfig = {0};

  /** Configure the global features of the ADC (Clock, Resolution, Data Alignment and number of conversion)
  */
  hadc1.Instance = ADC1;
  hadc1.Init.ClockPrescaler = ADC_CLOCK_SYNC_PCLK_DIV4;
  hadc1.Init.Resolution = ADC_RESOLUTION_12B;
  hadc1.Init.ScanConvMode = ADC_SCAN_DISABLE;
  hadc1.Init.ContinuousConvMode = DISABLE;
  hadc1.Init.DiscontinuousConvMode = DISABLE;
  hadc1.Init.ExternalTrigConvEdge = ADC_EXTERNALTRIGCONVEDGE_NONE;
  hadc1.Init.ExternalTrigConv = ADC_SOFTWARE_START;
  hadc1.Init.DataAlign = ADC_DATAALIGN_RIGHT;
  hadc1.Init.NbrOfConversion = 1;
  hadc1.Init.DMAContinuousRequests = DISABLE;
  hadc1.Init.EOCSelection = ADC_EOC_SINGLE_CONV;
  if (HAL_ADC_Init(&hadc1) != HAL_OK)
  {
    Error_Handler();
  }

  /** Configure for the selected ADC regular channel its corresponding rank in the sequencer and its sample time.
  */
  sConfig.Channel = ADC_CHANNEL_0;
  sConfig.Rank = ADC_REGULAR_RANK_1;
  sConfig.SamplingTime = ADC_SAMPLETIME_3CYCLES;
  if (HAL_ADC_ConfigChannel(&hadc1, &sConfig) != HAL_OK)
  {
    Error_Handler();
  }

}

static void MX_CRC_Init(void)
{

  hcrc.Instance = CRC;
  hcrc.Init.DefaultPolynomialUse = DEFAULT_POLYNOMIAL_ENABLE;
  hcrc.Init.DefaultInitValueUse = DEFAULT_INIT_VALUE_ENABLE;
  hcrc.Init.InputDataInversionMode = CRC_INPUTDATA_INVERSION_NONE;
  hcrc.Init.OutputDataInversionMode = CRC_OUTPUTDATA_INVERSION_DISABLE;
  hcrc.InputDataFormat = CRC_INPUTDATA_FORMAT_BYTES;
  if (HAL_CRC_Init(&hcrc) != HAL_OK)
  {
    Error_Handler();
  }

}

static void MX_I2C1_Init(void)
{

  hi2c1.Instance = I2C1;
  hi2c1.Init.Timing = 0x20404768;
  hi2c1.Init.OwnAddress1 = 0;
  hi2c1.Init.AddressingMode = I2C_ADDRESSINGMODE_7BIT;
  hi2c1.Init.DualAddressMode = I2C_DUALADDRESS_DISABLE;
  hi2c1.Init.OwnAddress2 = 0;
  hi2c1.Init.OwnAddress2Masks = I2C_OA2_NOMASK;
  hi2c1.Init.GeneralCallMode = I2C_GENERALCALL_DISABLE;
  hi2c1.Init.NoStretchMode = I2C_NOSTRETCH_DISABLE;
  if (HAL_I2C_Init(&hi2c1) != HAL_OK)
  {
    Error_Handler();
  }

  /** Configure Analogue filter
  */
  if (HAL_I2CEx_ConfigAnalogFilter(&hi2c1, I2C_ANALOGFILTER_ENABLE) != HAL_OK)
  {
    Error_Handler();
  }

  /** Configure Digital filter
  */
  if (HAL_I2CEx_ConfigDigitalFilter(&hi2c1, 0) != HAL_OK)
  {
    Error_Handler();
  }

}

static void MX_I2C2_Init(void)
{

  hi2c2.Instance = I2C2;
  hi2c2.Init.Timing = 0x20404768;
  hi2c2.Init.OwnAddress1 = 0;
  hi2c2.Init.AddressingMode = I2C_ADDRESSINGMODE_7BIT;
  hi2c2.Init.DualAddressMode = I2C_DUALADDRESS_DISABLE;
  hi2c2.Init.OwnAddress2 = 0;
  hi2c2.Init.OwnAddress2Masks = I2C_OA2_NOMASK;
  hi2c2.Init.GeneralCallMode = I2C_GENERALCALL_DISABLE;
  hi2c2.Init.NoStretchMode = I2C_NOSTRETCH_DISABLE;
  if (HAL_I2C_Init(&hi2c2) != HAL_OK)
  {
    Error_Handler();
  }

  /** Configure Analogue filter
  */
  if (HAL_I2CEx_ConfigAnalogFilter(&hi2c2, I2C_ANALOGFILTER_ENABLE) != HAL_OK)
  {
    Error_Handler();
  }

  /** Configure Digital filter
  */
  if (HAL_I2CEx_ConfigDigitalFilter(&hi2c2, 0) != HAL_OK)
  {
    Error_Handler();
  }

}

static void MX_I2C4_Init(void)
{

  hi2c4.Instance = I2C4;
  hi2c4.Init.Timing = 0x20404768;
  hi2c4.Init.OwnAddress1 = 0;
  hi2c4.Init.AddressingMode = I2C_ADDRESSINGMODE_7BIT;
  hi2c4.Init.DualAddressMode = I2C_DUALADDRESS_DISABLE;
  hi2c4.Init.OwnAddress2 = 0;
  hi2c4.Init.OwnAddress2Masks = I2C_OA2_NOMASK;
  hi2c4.Init.GeneralCallMode = I2C_GENERALCALL_DISABLE;
  hi2c4.Init.NoStretchMode = I2C_NOSTRETCH_DISABLE;
  if (HAL_I2C_Init(&hi2c4) != HAL_OK)
  {
    Error_Handler();
  }

  /** Configure Analogue filter
  */
  if (HAL_I2CEx_ConfigAnalogFilter(&hi2c4, I2C_ANALOGFILTER_ENABLE) != HAL_OK)
  {
    Error_Handler();
  }

  /** Configure Digital filter
  */
  if (HAL_I2CEx_ConfigDigitalFilter(&hi2c4, 0) != HAL_OK)
  {
    Error_Handler();
  }

}

static void MX_I2S2_Init(void)
{

  hi2s2.Instance = SPI2;
  hi2s2.Init.Mode = I2S_MODE_MASTER_TX;
  hi2s2.Init.Standard = I2S_STANDARD_PHILIPS;
  hi2s2.Init.DataFormat = I2S_DATAFORMAT_16B;
  hi2s2.Init.MCLKOutput = I2S_MCLKOUTPUT_DISABLE;
  hi2s2.Init.AudioFreq = I2S_AUDIOFREQ_8K;
  hi2s2.Init.CPOL = I2S_CPOL_LOW;
  hi2s2.Init.ClockSource = I2S_CLOCK_PLL;
  if (HAL_I2S_Init(&hi2s2) != HAL_OK)
  {
    Error_Handler();
  }

}

static void MX_QUADSPI_Init(void)
{

  /* QUADSPI parameter configuration*/
  hqspi.Instance = QUADSPI;
  hqspi.Init.ClockPrescaler = 1;
  hqspi.Init.FifoThreshold = 4;
  hqspi.Init.SampleShifting = QSPI_SAMPLE_SHIFTING_HALFCYCLE;
  hqspi.Init.FlashSize = 23;
  hqspi.Init.ChipSelectHighTime = QSPI_CS_HIGH_TIME_6_CYCLE;
  hqspi.Init.ClockMode = QSPI_CLOCK_MODE_0;
  hqspi.Init.FlashID = QSPI_FLASH_ID_1;
  hqspi.Init.DualFlash = QSPI_DUALFLASH_DISABLE;
  if (HAL_QSPI_Init(&hqspi) != HAL_OK)
  {
    Error_Handler();
  }

}

static void MX_RNG_Init(void)
{

  hrng.Instance = RNG;
  if (HAL_RNG_Init(&hrng) != HAL_OK)
  {
    Error_Handler();
  }

}

static void MX_SPI1_Init(void)
{

  /* SPI1 parameter configuration*/
  hspi1.Instance = SPI1;
  hspi1.Init.Mode = SPI_MODE_MASTER;
  hspi1.Init.Direction = SPI_DIRECTION_2LINES;
  hspi1.Init.DataSize = SPI_DATASIZE_8BIT;
  hspi1.Init.CLKPolarity = SPI_POLARITY_LOW;
  hspi1.Init.CLKPhase = SPI_PHASE_1EDGE;
  hspi1.Init.NSS = SPI_NSS_SOFT;
  hspi1.Init.BaudRatePrescaler = SPI_BAUDRATEPRESCALER_2;
  hspi1.Init.FirstBit = SPI_FIRSTBIT_MSB;
  hspi1.Init.TIMode = SPI_TIMODE_DISABLE;
  hspi1.Init.CRCCalculation = SPI_CRCCALCULATION_DISABLE;
  hspi1.Init.CRCPolynomial = 7;
  hspi1.Init.CRCLength = SPI_CRC_LENGTH_DATASIZE;
  hspi1.Init.NSSPMode = SPI_NSS_PULSE_ENABLE;
  if (HAL_SPI_Init(&hspi1) != HAL_OK)
  {
    Error_Handler();
  }

}

static void MX_SPI3_Init(void)
{

  /* SPI3 parameter configuration*/
  hspi3.Instance = SPI3;
  hspi3.Init.Mode = SPI_MODE_MASTER;
  hspi3.Init.Direction = SPI_DIRECTION_2LINES;
  hspi3.Init.DataSize = SPI_DATASIZE_8BIT;
  hspi3.Init.CLKPolarity = SPI_POLARITY_HIGH;
  hspi3.Init.CLKPhase = SPI_PHASE_2EDGE;
  hspi3.Init.NSS = SPI_NSS_SOFT;
  hspi3.Init.BaudRatePrescaler = SPI_BAUDRATEPRESCALER_32;
  hspi3.Init.FirstBit = SPI_FIRSTBIT_MSB;
  hspi3.Init.TIMode = SPI_TIMODE_DISABLE;
  hspi3.Init.CRCCalculation = SPI_CRCCALCULATION_DISABLE;
  hspi3.Init.CRCPolynomial = 7;
  hspi3.Init.CRCLength = SPI_CRC_LENGTH_DATASIZE;
  hspi3.Init.NSSPMode = SPI_NSS_PULSE_DISABLE;
  if (HAL_SPI_Init(&hspi3) != HAL_OK)
  {
    Error_Handler();
  }

}

static void MX_SPI6_Init(void)
{

  /* SPI6 parameter configuration*/
  hspi6.Instance = SPI6;
  hspi6.Init.Mode = SPI_MODE_MASTER;
  hspi6.Init.Direction = SPI_DIRECTION_2LINES;
  hspi6.Init.DataSize = SPI_DATASIZE_8BIT;
  hspi6.Init.CLKPolarity = SPI_POLARITY_LOW;
  hspi6.Init.CLKPhase = SPI_PHASE_1EDGE;
  hspi6.Init.NSS = SPI_NSS_SOFT;
  hspi6.Init.BaudRatePrescaler = SPI_BAUDRATEPRESCALER_2;
  hspi6.Init.FirstBit = SPI_FIRSTBIT_MSB;
  hspi6.Init.TIMode = SPI_TIMODE_DISABLE;
  hspi6.Init.CRCCalculation = SPI_CRCCALCULATION_DISABLE;
  hspi6.Init.CRCPolynomial = 7;
  hspi6.Init.CRCLength = SPI_CRC_LENGTH_DATASIZE;
  hspi6.Init.NSSPMode = SPI_NSS_PULSE_ENABLE;
  if (HAL_SPI_Init(&hspi6) != HAL_OK)
  {
    Error_Handler();
  }

}

static void MX_TIM1_Init(void)
{

  TIM_ClockConfigTypeDef sClockSourceConfig = {0};
  TIM_MasterConfigTypeDef sMasterConfig = {0};
  TIM_OC_InitTypeDef sConfigOC = {0};
  TIM_BreakDeadTimeConfigTypeDef sBreakDeadTimeConfig = {0};

  htim1.Instance = TIM1;
  htim1.Init.Prescaler = 215;
  htim1.Init.CounterMode = TIM_COUNTERMODE_UP;
  htim1.Init.Period = 20000;
  htim1.Init.ClockDivision = TIM_CLOCKDIVISION_DIV1;
  htim1.Init.RepetitionCounter = 0;
  htim1.Init.AutoReloadPreload = TIM_AUTORELOAD_PRELOAD_DISABLE;
  if (HAL_TIM_Base_Init(&htim1) != HAL_OK)
  {
    Error_Handler();
  }
  sClockSourceConfig.ClockSource = TIM_CLOCKSOURCE_INTERNAL;
  if (HAL_TIM_ConfigClockSource(&htim1, &sClockSourceConfig) != HAL_OK)
  {
    Error_Handler();
  }
  if (HAL_TIM_PWM_Init(&htim1) != HAL_OK)
  {
    Error_Handler();
  }
  sMasterConfig.MasterOutputTrigger = TIM_TRGO_RESET;
  sMasterConfig.MasterOutputTrigger2 = TIM_TRGO2_RESET;
  sMasterConfig.MasterSlaveMode = TIM_MASTERSLAVEMODE_DISABLE;
  if (HAL_TIMEx_MasterConfigSynchronization(&htim1, &sMasterConfig) != HAL_OK)
  {
    Error_Handler();
  }
  sConfigOC.OCMode = TIM_OCMODE_PWM1;
  sConfigOC.Pulse = 1500;
  sConfigOC.OCPolarity = TIM_OCPOLARITY_HIGH;
  sConfigOC.OCNPolarity = TIM_OCNPOLARITY_HIGH;
  sConfigOC.OCFastMode = TIM_OCFAST_DISABLE;
  sConfigOC.OCIdleState = TIM_OCIDLESTATE_RESET;
  sConfigOC.OCNIdleState = TIM_OCNIDLESTATE_RESET;
  if (HAL_TIM_PWM_ConfigChannel(&htim1, &sConfigOC, TIM_CHANNEL_1) != HAL_OK)
  {
    Error_Handler();
  }
  sConfigOC.Pulse = 0;
  if (HAL_TIM_PWM_ConfigChannel(&htim1, &sConfigOC, TIM_CHANNEL_2) != HAL_OK)
  {
    Error_Handler();
  }
  if (HAL_TIM_PWM_ConfigChannel(&htim1, &sConfigOC, TIM_CHANNEL_3) != HAL_OK)
  {
    Error_Handler();
  }
  if (HAL_TIM_PWM_ConfigChannel(&htim1, &sConfigOC, TIM_CHANNEL_4) != HAL_OK)
  {
    Error_Handler();
  }
  sBreakDeadTimeConfig.OffStateRunMode = TIM_OSSR_DISABLE;
  sBreakDeadTimeConfig.OffStateIDLEMode = TIM_OSSI_DISABLE;
  sBreakDeadTimeConfig.LockLevel = TIM_LOCKLEVEL_OFF;
  sBreakDeadTimeConfig.DeadTime = 0;
  sBreakDeadTimeConfig.BreakState = TIM_BREAK_DISABLE;
  sBreakDeadTimeConfig.BreakPolarity = TIM_BREAKPOLARITY_HIGH;
  sBreakDeadTimeConfig.BreakFilter = 0;
  sBreakDeadTimeConfig.Break2State = TIM_BREAK2_DISABLE;
  sBreakDeadTimeConfig.Break2Polarity = TIM_BREAK2POLARITY_HIGH;
  sBreakDeadTimeConfig.Break2Filter = 0;
  sBreakDeadTimeConfig.AutomaticOutput = TIM_AUTOMATICOUTPUT_DISABLE;
  if (HAL_TIMEx_ConfigBreakDeadTime(&htim1, &sBreakDeadTimeConfig) != HAL_OK)
  {
    Error_Handler();
  }
  HAL_TIM_MspPostInit(&htim1);

}

static void MX_TIM2_Init(void)
{

  TIM_ClockConfigTypeDef sClockSourceConfig = {0};
  TIM_MasterConfigTypeDef sMasterConfig = {0};
  TIM_IC_InitTypeDef sConfigIC = {0};

  htim2.Instance = TIM2;
  htim2.Init.Prescaler = 0;
  htim2.Init.CounterMode = TIM_COUNTERMODE_UP;
  htim2.Init.Period = 4294967295;
  htim2.Init.ClockDivision = TIM_CLOCKDIVISION_DIV1;
  htim2.Init.AutoReloadPreload = TIM_AUTORELOAD_PRELOAD_DISABLE;
  if (HAL_TIM_Base_Init(&htim2) != HAL_OK)
  {
    Error_Handler();
  }
  sClockSourceConfig.ClockSource = TIM_CLOCKSOURCE_INTERNAL;
  if (HAL_TIM_ConfigClockSource(&htim2, &sClockSourceConfig) != HAL_OK)
  {
    Error_Handler();
  }
  if (HAL_TIM_IC_Init(&htim2) != HAL_OK)
  {
    Error_Handler();
  }
  sMasterConfig.MasterOutputTrigger = TIM_TRGO_RESET;
  sMasterConfig.MasterSlaveMode = TIM_MASTERSLAVEMODE_DISABLE;
  if (HAL_TIMEx_MasterConfigSynchronization(&htim2, &sMasterConfig) != HAL_OK)
  {
    Error_Handler();
  }
  sConfigIC.ICPolarity = TIM_INPUTCHANNELPOLARITY_RISING;
  sConfigIC.ICSelection = TIM_ICSELECTION_DIRECTTI;
  sConfigIC.ICPrescaler = TIM_ICPSC_DIV1;
  sConfigIC.ICFilter = 0;
  if (HAL_TIM_IC_ConfigChannel(&htim2, &sConfigIC, TIM_CHANNEL_1) != HAL_OK)
  {
    Error_Handler();
  }

}

static void MX_TIM3_Init(void)
{

  TIM_ClockConfigTypeDef sClockSourceConfig = {0};
  TIM_MasterConfigTypeDef sMasterConfig = {0};

  htim3.Instance = TIM3;
  htim3.Init.Prescaler = 0;
  htim3.Init.CounterMode = TIM_COUNTERMODE_UP;
  htim3.Init.Period = 65535;
  htim3.Init.ClockDivision = TIM_CLOCKDIVISION_DIV1;
  htim3.Init.AutoReloadPreload = TIM_AUTORELOAD_PRELOAD_DISABLE;
  if (HAL_TIM_Base_Init(&htim3) != HAL_OK)
  {
    Error_Handler();
  }
  sClockSourceConfig.ClockSource = TIM_CLOCKSOURCE_INTERNAL;
  if (HAL_TIM_ConfigClockSource(&htim3, &sClockSourceConfig) != HAL_OK)
  {
    Error_Handler();
  }
  sMasterConfig.MasterOutputTrigger = TIM_TRGO_RESET;
  sMasterConfig.MasterSlaveMode = TIM_MASTERSLAVEMODE_DISABLE;
  if (HAL_TIMEx_MasterConfigSynchronization(&htim3, &sMasterConfig) != HAL_OK)
  {
    Error_Handler();
  }

}

static void MX_TIM8_Init(void)
{

  TIM_ClockConfigTypeDef sClockSourceConfig = {0};
  TIM_MasterConfigTypeDef sMasterConfig = {0};
  TIM_OC_InitTypeDef sConfigOC = {0};
  TIM_BreakDeadTimeConfigTypeDef sBreakDeadTimeConfig = {0};

  htim8.Instance = TIM8;
  htim8.Init.Prescaler = 0;
  htim8.Init.CounterMode = TIM_COUNTERMODE_UP;
  htim8.Init.Period = 65535;
  htim8.Init.ClockDivision = TIM_CLOCKDIVISION_DIV1;
  htim8.Init.RepetitionCounter = 0;
  htim8.Init.AutoReloadPreload = TIM_AUTORELOAD_PRELOAD_DISABLE;
  if (HAL_TIM_Base_Init(&htim8) != HAL_OK)
  {
    Error_Handler();
  }
  sClockSourceConfig.ClockSource = TIM_CLOCKSOURCE_INTERNAL;
  if (HAL_TIM_ConfigClockSource(&htim8, &sClockSourceConfig) != HAL_OK)
  {
    Error_Handler();
  }
  if (HAL_TIM_PWM_Init(&htim8) != HAL_OK)
  {
    Error_Handler();
  }
  if (HAL_TIM_OC_Init(&htim8) != HAL_OK)
  {
    Error_Handler();
  }
  sMasterConfig.MasterOutputTrigger = TIM_TRGO_RESET;
  sMasterConfig.MasterOutputTrigger2 = TIM_TRGO2_RESET;
  sMasterConfig.MasterSlaveMode = TIM_MASTERSLAVEMODE_DISABLE;
  if (HAL_TIMEx_MasterConfigSynchronization(&htim8, &sMasterConfig) != HAL_OK)
  {
    Error_Handler();
  }
  sConfigOC.OCMode = TIM_OCMODE_PWM1;
  sConfigOC.Pulse = 0;
  sConfigOC.OCPolarity = TIM_OCPOLARITY_HIGH;
  sConfigOC.OCNPolarity = TIM_OCNPOLARITY_HIGH;
  sConfigOC.OCFastMode = TIM_OCFAST_DISABLE;
  sConfigOC.OCIdleState = TIM_OCIDLESTATE_RESET;
  sConfigOC.OCNIdleState = TIM_OCNIDLESTATE_RESET;
  if (HAL_TIM_PWM_ConfigChannel(&htim8, &sConfigOC, TIM_CHANNEL_1) != HAL_OK)
  {
    Error_Handler();
  }
  if (HAL_TIM_PWM_ConfigChannel(&htim8, &sConfigOC, TIM_CHANNEL_2) != HAL_OK)
  {
    Error_Handler();
  }
  sConfigOC.OCMode = TIM_OCMODE_TIMING;
  if (HAL_TIM_OC_ConfigChannel(&htim8, &sConfigOC, TIM_CHANNEL_3) != HAL_OK)
  {
    Error_Handler();
  }
  sConfigOC.OCMode = TIM_OCMODE_PWM1;
  if (HAL_TIM_PWM_ConfigChannel(&htim8, &sConfigOC, TIM_CHANNEL_4) != HAL_OK)
  {
    Error_Handler();
  }
  sBreakDeadTimeConfig.OffStateRunMode = TIM_OSSR_DISABLE;
  sBreakDeadTimeConfig.OffStateIDLEMode = TIM_OSSI_DISABLE;
  sBreakDeadTimeConfig.LockLevel = TIM_LOCKLEVEL_OFF;
  sBreakDeadTimeConfig.DeadTime = 0;
  sBreakDeadTimeConfig.BreakState = TIM_BREAK_DISABLE;
  sBreakDeadTimeConfig.BreakPolarity = TIM_BREAKPOLARITY_HIGH;
  sBreakDeadTimeConfig.BreakFilter = 0;
  sBreakDeadTimeConfig.Break2State = TIM_BREAK2_DISABLE;
  sBreakDeadTimeConfig.Break2Polarity = TIM_BREAK2POLARITY_HIGH;
  sBreakDeadTimeConfig.Break2Filter = 0;
  sBreakDeadTimeConfig.AutomaticOutput = TIM_AUTOMATICOUTPUT_DISABLE;
  if (HAL_TIMEx_ConfigBreakDeadTime(&htim8, &sBreakDeadTimeConfig) != HAL_OK)
  {
    Error_Handler();
  }
  HAL_TIM_MspPostInit(&htim8);

}

static void MX_UART4_Init(void)
{

  huart4.Instance = UART4;
  huart4.Init.BaudRate = 115200;
  huart4.Init.WordLength = UART_WORDLENGTH_8B;
  huart4.Init.StopBits = UART_STOPBITS_1;
  huart4.Init.Parity = UART_PARITY_NONE;
  huart4.Init.Mode = UART_MODE_TX_RX;
  huart4.Init.HwFlowCtl = UART_HWCONTROL_NONE;
  huart4.Init.OverSampling = UART_OVERSAMPLING_16;
  huart4.Init.OneBitSampling = UART_ONE_BIT_SAMPLE_DISABLE;
  huart4.AdvancedInit.AdvFeatureInit = UART_ADVFEATURE_NO_INIT;
  if (HAL_UART_Init(&huart4) != HAL_OK)
  {
    Error_Handler();
  }

}

static void MX_UART5_Init(void)
{

  huart5.Instance = UART5;
  huart5.Init.BaudRate = 115200;
  huart5.Init.WordLength = UART_WORDLENGTH_8B;
  huart5.Init.StopBits = UART_STOPBITS_1;
  huart5.Init.Parity = UART_PARITY_NONE;
  huart5.Init.Mode = UART_MODE_TX_RX;
  huart5.Init.HwFlowCtl = UART_HWCONTROL_NONE;
  huart5.Init.OverSampling = UART_OVERSAMPLING_16;
  huart5.Init.OneBitSampling = UART_ONE_BIT_SAMPLE_DISABLE;
  huart5.AdvancedInit.AdvFeatureInit = UART_ADVFEATURE_NO_INIT;
  if (HAL_UART_Init(&huart5) != HAL_OK)
  {
    Error_Handler();
  }

}

static void MX_USART1_UART_Init(void)
{

  huart1.Instance = USART1;
  huart1.Init.BaudRate = 115200;
  huart1.Init.WordLength = UART_WORDLENGTH_8B;
  huart1.Init.StopBits = UART_STOPBITS_1;
  huart1.Init.Parity = UART_PARITY_NONE;
  huart1.Init.Mode = UART_MODE_TX_RX;
  huart1.Init.HwFlowCtl = UART_HWCONTROL_NONE;
  huart1.Init.OverSampling = UART_OVERSAMPLING_16;
  huart1.Init.OneBitSampling = UART_ONE_BIT_SAMPLE_DISABLE;
  huart1.AdvancedInit.AdvFeatureInit = UART_ADVFEATURE_NO_INIT;
  if (HAL_UART_Init(&huart1) != HAL_OK)
  {
    Error_Handler();
  }

}

static void MX_USART2_UART_Init(void)
{

  huart2.Instance = USART2;
  huart2.Init.BaudRate = 115200;
  huart2.Init.WordLength = UART_WORDLENGTH_8B;
  huart2.Init.StopBits = UART_STOPBITS_1;
  huart2.Init.Parity = UART_PARITY_NONE;
  huart2.Init.Mode = UART_MODE_TX_RX;
  huart2.Init.HwFlowCtl = UART_HWCONTROL_CTS;
  huart2.Init.OverSampling = UART_OVERSAMPLING_16;
  huart2.Init.OneBitSampling = UART_ONE_BIT_SAMPLE_DISABLE;
  huart2.AdvancedInit.AdvFeatureInit = UART_ADVFEATURE_NO_INIT;
  if (HAL_UART_Init(&huart2) != HAL_OK)
  {
    Error_Handler();
  }

}

static void MX_USART3_UART_Init(void)
{

  huart3.Instance = USART3;
  huart3.Init.BaudRate = 115200;
  huart3.Init.WordLength = UART_WORDLENGTH_8B;
  huart3.Init.StopBits = UART_STOPBITS_1;
  huart3.Init.Parity = UART_PARITY_NONE;
  huart3.Init.Mode = UART_MODE_TX_RX;
  huart3.Init.HwFlowCtl = UART_HWCONTROL_NONE;
  huart3.Init.OverSampling = UART_OVERSAMPLING_16;
  huart3.Init.OneBitSampling = UART_ONE_BIT_SAMPLE_DISABLE;
  huart3.AdvancedInit.AdvFeatureInit = UART_ADVFEATURE_NO_INIT;
  if (HAL_UART_Init(&huart3) != HAL_OK)
  {
    Error_Handler();
  }

}

static void MX_USART6_UART_Init(void)
{

  huart6.Instance = USART6;
  huart6.Init.BaudRate = 115200;
  huart6.Init.WordLength = UART_WORDLENGTH_8B;
  huart6.Init.StopBits = UART_STOPBITS_1;
  huart6.Init.Parity = UART_PARITY_NONE;
  huart6.Init.Mode = UART_MODE_TX_RX;
  huart6.Init.HwFlowCtl = UART_HWCONTROL_NONE;
  huart6.Init.OverSampling = UART_OVERSAMPLING_16;
  huart6.Init.OneBitSampling = UART_ONE_BIT_SAMPLE_DISABLE;
  huart6.AdvancedInit.AdvFeatureInit = UART_ADVFEATURE_NO_INIT;
  if (HAL_UART_Init(&huart6) != HAL_OK)
  {
    Error_Handler();
  }

}

static void MX_DMA_Init(void)
{

  /* DMA controller clock enable */
  __HAL_RCC_DMA2_CLK_ENABLE();

  /* DMA interrupt init */
  /* DMA2_Stream2_IRQn interrupt configuration */
  HAL_NVIC_SetPriority(DMA2_Stream2_IRQn, 5, 0);
  HAL_NVIC_EnableIRQ(DMA2_Stream2_IRQn);
  /* DMA2_Stream5_IRQn interrupt configuration */
  HAL_NVIC_SetPriority(DMA2_Stream5_IRQn, 5, 0);
  HAL_NVIC_EnableIRQ(DMA2_Stream5_IRQn);
  /* DMA2_Stream7_IRQn interrupt configuration */
  HAL_NVIC_SetPriority(DMA2_Stream7_IRQn, 5, 0);
  HAL_NVIC_EnableIRQ(DMA2_Stream7_IRQn);

}

static void MX_GPIO_Init(void)
{
  GPIO_InitTypeDef GPIO_InitStruct = {0};

  /* GPIO Ports Clock Enable */
  __HAL_RCC_GPIOE_CLK_ENABLE();
  __HAL_RCC_GPIOI_CLK_ENABLE();
  __HAL_RCC_GPIOC_CLK_ENABLE();
  __HAL_RCC_GPIOF_CLK_ENABLE();
  __HAL_RCC_GPIOH_CLK_ENABLE();
  __HAL_RCC_GPIOA_CLK_ENABLE();
  __HAL_RCC_GPIOB_CLK_ENABLE();
  __HAL_RCC_GPIOG_CLK_ENABLE();
  __HAL_RCC_GPIOD_CLK_ENABLE();

  /*Configure GPIO pin Output Level */
  HAL_GPIO_WritePin(GPIOE, TFT_CS_Pin|TFT_EN_Pin|VPWM_OE_Pin|TOF6_En_Pin
                          |TOF6_LPn_Pin|AUDIO_MODE_Pin|CTP_RESET_Pin, GPIO_PIN_RESET);

  /*Configure GPIO pin Output Level */
  HAL_GPIO_WritePin(VPWM_D1_GPIO_Port, VPWM_D1_Pin, GPIO_PIN_SET);

  /*Configure GPIO pin Output Level */
  HAL_GPIO_WritePin(GPIOI, VPWM_D0_Pin|TLM_EN_Pin|TOF3_LPn_Pin|TOF2_LPn_Pin
                          |TFT_RESET_Pin|TFT_RD_Pin|TFT_DC_Pin, GPIO_PIN_RESET);

  /*Configure GPIO pin Output Level */
  HAL_GPIO_WritePin(GPIOF, WIFI_PWREN_Pin|WIFI_CS_Pin|WIFI_WAKE_Pin|WIFI_IRQ_Pin
                          |RADIO_IO4_Pin, GPIO_PIN_RESET);

  /*Configure GPIO pin Output Level */
  HAL_GPIO_WritePin(GPIOC, TLM_IO3_Pin|TLM_IO2_Pin|RADIO_IO1_Pin|RADIO_IO2_Pin, GPIO_PIN_RESET);

  /*Configure GPIO pin Output Level */
  HAL_GPIO_WritePin(GPIOH, WIFI_EN_Pin|WIFI_RESET_Pin|TLM_IO4_Pin|TLM_IO5_Pin
                          |TOF5_En_Pin|TOF5_LPn_Pin|TOF4_En_Pin|TOF4_LPn_Pin
                          |TOF3_En_Pin, GPIO_PIN_RESET);

  /*Configure GPIO pin Output Level */
  HAL_GPIO_WritePin(GPIOB, RADIO_IO3_Pin|RADIO_IO5_Pin|PPM_OE_Pin|BKL_PWM_Pin
                          |AUDIO_EN_Pin|AUDIO_GAIN_Pin, GPIO_PIN_RESET);

  /*Configure GPIO pin Output Level */
  HAL_GPIO_WritePin(GPIOF, LED_ERROR_Pin|LED_COMM_Pin, GPIO_PIN_SET);

  /*Configure GPIO pin Output Level */
  HAL_GPIO_WritePin(GPIOG, LED_HB_Pin|LED_ACTY_Pin, GPIO_PIN_SET);

  /*Configure GPIO pin Output Level */
  HAL_GPIO_WritePin(LED_READY_GPIO_Port, LED_READY_Pin, GPIO_PIN_SET);

  /*Configure GPIO pin Output Level */
  HAL_GPIO_WritePin(GPIOD, DOF_NRST_Pin|DOF_PS0_Pin|DOF_PS1_Pin|DOF_BOOTN_Pin
                          |DOF_CS_Pin, GPIO_PIN_SET);

  /*Configure GPIO pin Output Level */
  HAL_GPIO_WritePin(GPIOD, DOF_CLKSEL_Pin|NVRAM_HOLD_Pin|TOF2_En_Pin|TOF1_LPn_Pin
                          |TOF1_En_Pin, GPIO_PIN_RESET);

  /*Configure GPIO pin Output Level */
  HAL_GPIO_WritePin(GPIOG, NVRAM_WP_Pin|NVRAM_CS_Pin|FLASH_HOLD_Pin|FLASH_CS_Pin
                          |FLASH_WP_Pin, GPIO_PIN_RESET);

  /*Configure GPIO pin Output Level */
  HAL_GPIO_WritePin(SBUS_OE_GPIO_Port, SBUS_OE_Pin, GPIO_PIN_RESET);

  /*Configure GPIO pin : TFT_CS_Pin */
  GPIO_InitStruct.Pin = TFT_CS_Pin;
  GPIO_InitStruct.Mode = GPIO_MODE_OUTPUT_PP;
  GPIO_InitStruct.Pull = GPIO_PULLUP;
  GPIO_InitStruct.Speed = GPIO_SPEED_FREQ_LOW;
  HAL_GPIO_Init(TFT_CS_GPIO_Port, &GPIO_InitStruct);

  /*Configure GPIO pins : TFT_EN_Pin VPWM_OE_Pin LED_READY_Pin TOF6_En_Pin
                           TOF6_LPn_Pin AUDIO_MODE_Pin CTP_RESET_Pin */
  GPIO_InitStruct.Pin = TFT_EN_Pin|VPWM_OE_Pin|LED_READY_Pin|TOF6_En_Pin
                          |TOF6_LPn_Pin|AUDIO_MODE_Pin|CTP_RESET_Pin;
  GPIO_InitStruct.Mode = GPIO_MODE_OUTPUT_PP;
  GPIO_InitStruct.Pull = GPIO_NOPULL;
  GPIO_InitStruct.Speed = GPIO_SPEED_FREQ_LOW;
  HAL_GPIO_Init(GPIOE, &GPIO_InitStruct);

  /*Configure GPIO pins : VPWM_D1_Pin VPWM_D0_Pin TLM_EN_Pin TOF3_LPn_Pin
                           TOF2_LPn_Pin TFT_RESET_Pin TFT_RD_Pin TFT_DC_Pin */
  GPIO_InitStruct.Pin = VPWM_D1_Pin|VPWM_D0_Pin|TLM_EN_Pin|TOF3_LPn_Pin
                          |TOF2_LPn_Pin|TFT_RESET_Pin|TFT_RD_Pin|TFT_DC_Pin;
  GPIO_InitStruct.Mode = GPIO_MODE_OUTPUT_PP;
  GPIO_InitStruct.Pull = GPIO_NOPULL;
  GPIO_InitStruct.Speed = GPIO_SPEED_FREQ_LOW;
  HAL_GPIO_Init(GPIOI, &GPIO_InitStruct);

  /*Configure GPIO pin : VPWM_STAT_Pin */
  GPIO_InitStruct.Pin = VPWM_STAT_Pin;
  GPIO_InitStruct.Mode = GPIO_MODE_INPUT;
  GPIO_InitStruct.Pull = GPIO_NOPULL;
  HAL_GPIO_Init(VPWM_STAT_GPIO_Port, &GPIO_InitStruct);

  /*Configure GPIO pins : WIFI_PWREN_Pin WIFI_WAKE_Pin WIFI_IRQ_Pin RADIO_IO4_Pin
                           LED_ERROR_Pin LED_COMM_Pin */
  GPIO_InitStruct.Pin = WIFI_PWREN_Pin|WIFI_WAKE_Pin|WIFI_IRQ_Pin|RADIO_IO4_Pin
                          |LED_ERROR_Pin|LED_COMM_Pin;
  GPIO_InitStruct.Mode = GPIO_MODE_OUTPUT_PP;
  GPIO_InitStruct.Pull = GPIO_NOPULL;
  GPIO_InitStruct.Speed = GPIO_SPEED_FREQ_LOW;
  HAL_GPIO_Init(GPIOF, &GPIO_InitStruct);

  /*Configure GPIO pin : WIFI_CS_Pin */
  GPIO_InitStruct.Pin = WIFI_CS_Pin;
  GPIO_InitStruct.Mode = GPIO_MODE_OUTPUT_PP;
  GPIO_InitStruct.Pull = GPIO_PULLUP;
  GPIO_InitStruct.Speed = GPIO_SPEED_FREQ_LOW;
  HAL_GPIO_Init(WIFI_CS_GPIO_Port, &GPIO_InitStruct);

  /*Configure GPIO pins : TLM_IO3_Pin TLM_IO2_Pin RADIO_IO1_Pin RADIO_IO2_Pin */
  GPIO_InitStruct.Pin = TLM_IO3_Pin|TLM_IO2_Pin|RADIO_IO1_Pin|RADIO_IO2_Pin;
  GPIO_InitStruct.Mode = GPIO_MODE_OUTPUT_PP;
  GPIO_InitStruct.Pull = GPIO_NOPULL;
  GPIO_InitStruct.Speed = GPIO_SPEED_FREQ_LOW;
  HAL_GPIO_Init(GPIOC, &GPIO_InitStruct);

  /*Configure GPIO pins : WIFI_EN_Pin WIFI_RESET_Pin TLM_IO4_Pin TLM_IO5_Pin
                           TOF5_En_Pin TOF5_LPn_Pin TOF4_En_Pin TOF4_LPn_Pin
                           TOF3_En_Pin */
  GPIO_InitStruct.Pin = WIFI_EN_Pin|WIFI_RESET_Pin|TLM_IO4_Pin|TLM_IO5_Pin
                          |TOF5_En_Pin|TOF5_LPn_Pin|TOF4_En_Pin|TOF4_LPn_Pin
                          |TOF3_En_Pin;
  GPIO_InitStruct.Mode = GPIO_MODE_OUTPUT_PP;
  GPIO_InitStruct.Pull = GPIO_NOPULL;
  GPIO_InitStruct.Speed = GPIO_SPEED_FREQ_LOW;
  HAL_GPIO_Init(GPIOH, &GPIO_InitStruct);

  /*Configure GPIO pins : RADIO_IO3_Pin RADIO_IO5_Pin PPM_OE_Pin BKL_PWM_Pin
                           AUDIO_EN_Pin AUDIO_GAIN_Pin */
  GPIO_InitStruct.Pin = RADIO_IO3_Pin|RADIO_IO5_Pin|PPM_OE_Pin|BKL_PWM_Pin
                          |AUDIO_EN_Pin|AUDIO_GAIN_Pin;
  GPIO_InitStruct.Mode = GPIO_MODE_OUTPUT_PP;
  GPIO_InitStruct.Pull = GPIO_NOPULL;
  GPIO_InitStruct.Speed = GPIO_SPEED_FREQ_LOW;
  HAL_GPIO_Init(GPIOB, &GPIO_InitStruct);

  /*Configure GPIO pins : LED_HB_Pin LED_ACTY_Pin NVRAM_WP_Pin */
  GPIO_InitStruct.Pin = LED_HB_Pin|LED_ACTY_Pin|NVRAM_WP_Pin;
  GPIO_InitStruct.Mode = GPIO_MODE_OUTPUT_PP;
  GPIO_InitStruct.Pull = GPIO_NOPULL;
  GPIO_InitStruct.Speed = GPIO_SPEED_FREQ_LOW;
  HAL_GPIO_Init(GPIOG, &GPIO_InitStruct);

  /*Configure GPIO pin : TOF6_GPIO_Pin */
  GPIO_InitStruct.Pin = TOF6_GPIO_Pin;
  GPIO_InitStruct.Mode = GPIO_MODE_INPUT;
  GPIO_InitStruct.Pull = GPIO_NOPULL;
  HAL_GPIO_Init(TOF6_GPIO_GPIO_Port, &GPIO_InitStruct);

  /*Configure GPIO pins : TOF5_GPIO_Pin TOF4_GPIO_Pin PSENS_INT_Pin GPOUT_Pin
                           VSEL_OUT_Pin */
  GPIO_InitStruct.Pin = TOF5_GPIO_Pin|TOF4_GPIO_Pin|PSENS_INT_Pin|GPOUT_Pin
                          |VSEL_OUT_Pin;
  GPIO_InitStruct.Mode = GPIO_MODE_INPUT;
  GPIO_InitStruct.Pull = GPIO_NOPULL;
  HAL_GPIO_Init(GPIOH, &GPIO_InitStruct);

  /*Configure GPIO pin : DOF_INT_Pin */
  GPIO_InitStruct.Pin = DOF_INT_Pin;
  GPIO_InitStruct.Mode = GPIO_MODE_INPUT;
  GPIO_InitStruct.Pull = GPIO_PULLUP;
  HAL_GPIO_Init(DOF_INT_GPIO_Port, &GPIO_InitStruct);

  /*Configure GPIO pins : DOF_NRST_Pin DOF_PS0_Pin DOF_PS1_Pin DOF_BOOTN_Pin
                           DOF_CS_Pin */
  GPIO_InitStruct.Pin = DOF_NRST_Pin|DOF_PS0_Pin|DOF_PS1_Pin|DOF_BOOTN_Pin
                          |DOF_CS_Pin;
  GPIO_InitStruct.Mode = GPIO_MODE_OUTPUT_PP;
  GPIO_InitStruct.Pull = GPIO_PULLUP;
  GPIO_InitStruct.Speed = GPIO_SPEED_FREQ_LOW;
  HAL_GPIO_Init(GPIOD, &GPIO_InitStruct);

  /*Configure GPIO pin : DOF_CLKSEL_Pin */
  GPIO_InitStruct.Pin = DOF_CLKSEL_Pin;
  GPIO_InitStruct.Mode = GPIO_MODE_OUTPUT_PP;
  GPIO_InitStruct.Pull = GPIO_PULLDOWN;
  GPIO_InitStruct.Speed = GPIO_SPEED_FREQ_LOW;
  HAL_GPIO_Init(DOF_CLKSEL_GPIO_Port, &GPIO_InitStruct);

  /*Configure GPIO pins : NVRAM_HOLD_Pin TOF2_En_Pin TOF1_LPn_Pin TOF1_En_Pin */
  GPIO_InitStruct.Pin = NVRAM_HOLD_Pin|TOF2_En_Pin|TOF1_LPn_Pin|TOF1_En_Pin;
  GPIO_InitStruct.Mode = GPIO_MODE_OUTPUT_PP;
  GPIO_InitStruct.Pull = GPIO_NOPULL;
  GPIO_InitStruct.Speed = GPIO_SPEED_FREQ_LOW;
  HAL_GPIO_Init(GPIOD, &GPIO_InitStruct);

  /*Configure GPIO pins : NVRAM_CS_Pin FLASH_HOLD_Pin FLASH_CS_Pin FLASH_WP_Pin */
  GPIO_InitStruct.Pin = NVRAM_CS_Pin|FLASH_HOLD_Pin|FLASH_CS_Pin|FLASH_WP_Pin;
  GPIO_InitStruct.Mode = GPIO_MODE_OUTPUT_PP;
  GPIO_InitStruct.Pull = GPIO_PULLUP;
  GPIO_InitStruct.Speed = GPIO_SPEED_FREQ_LOW;
  HAL_GPIO_Init(GPIOG, &GPIO_InitStruct);

  /*Configure GPIO pins : PGOOD_5V_Pin PGOOD_3V3_Pin CPT_INT_Pin */
  GPIO_InitStruct.Pin = PGOOD_5V_Pin|PGOOD_3V3_Pin|CPT_INT_Pin;
  GPIO_InitStruct.Mode = GPIO_MODE_INPUT;
  GPIO_InitStruct.Pull = GPIO_NOPULL;
  HAL_GPIO_Init(GPIOG, &GPIO_InitStruct);

  /*Configure GPIO pin : SBUS_OE_Pin */
  GPIO_InitStruct.Pin = SBUS_OE_Pin;
  GPIO_InitStruct.Mode = GPIO_MODE_OUTPUT_PP;
  GPIO_InitStruct.Pull = GPIO_NOPULL;
  GPIO_InitStruct.Speed = GPIO_SPEED_FREQ_LOW;
  HAL_GPIO_Init(SBUS_OE_GPIO_Port, &GPIO_InitStruct);

  /*Configure GPIO pins : TOF3_GPIO_Pin TOF2_GPIO_Pin */
  GPIO_InitStruct.Pin = TOF3_GPIO_Pin|TOF2_GPIO_Pin;
  GPIO_InitStruct.Mode = GPIO_MODE_INPUT;
  GPIO_InitStruct.Pull = GPIO_NOPULL;
  HAL_GPIO_Init(GPIOI, &GPIO_InitStruct);

  /*Configure GPIO pin : TOF1_GPIO_Pin */
  GPIO_InitStruct.Pin = TOF1_GPIO_Pin;
  GPIO_InitStruct.Mode = GPIO_MODE_INPUT;
  GPIO_InitStruct.Pull = GPIO_NOPULL;
  HAL_GPIO_Init(TOF1_GPIO_GPIO_Port, &GPIO_InitStruct);

}

void StartDefaultTask(void *argument)
{
  /* USER CODE BEGIN 5 */

       MX_TouchGFX_Init();
			  /* Call PreOsInit function */
			  MX_TouchGFX_PreOSInit();

		MX_TouchGFX_Process();

  /* Infinite loop */
  for(;;)
  {
    osDelay(1);
  }
  /* USER CODE END 5 */
}

 /* MPU Configuration */

void MPU_Config(void)
{
  MPU_Region_InitTypeDef MPU_InitStruct = {0};

  /* Disables the MPU */
  HAL_MPU_Disable();

  /** Initializes and configures the Region and the memory to be protected
  */
  MPU_InitStruct.Enable = MPU_REGION_ENABLE;
  MPU_InitStruct.Number = MPU_REGION_NUMBER0;
  MPU_InitStruct.BaseAddress = 0x20000000;
  MPU_InitStruct.Size = MPU_REGION_SIZE_512MB;
  MPU_InitStruct.SubRegionDisable = 0x0;
  MPU_InitStruct.TypeExtField = MPU_TEX_LEVEL1;
  MPU_InitStruct.AccessPermission = MPU_REGION_FULL_ACCESS;
  MPU_InitStruct.DisableExec = MPU_INSTRUCTION_ACCESS_DISABLE;
  MPU_InitStruct.IsShareable = MPU_ACCESS_SHAREABLE;
  MPU_InitStruct.IsCacheable = MPU_ACCESS_NOT_CACHEABLE;
  MPU_InitStruct.IsBufferable = MPU_ACCESS_NOT_BUFFERABLE;

  HAL_MPU_ConfigRegion(&MPU_InitStruct);

  /** Initializes and configures the Region and the memory to be protected
  */
  MPU_InitStruct.Number = MPU_REGION_NUMBER1;
  MPU_InitStruct.BaseAddress = 0x90000000;
  MPU_InitStruct.TypeExtField = MPU_TEX_LEVEL0;
  MPU_InitStruct.AccessPermission = MPU_REGION_NO_ACCESS;
  MPU_InitStruct.IsShareable = MPU_ACCESS_NOT_SHAREABLE;

  HAL_MPU_ConfigRegion(&MPU_InitStruct);

  /** Initializes and configures the Region and the memory to be protected
  */
  MPU_InitStruct.Number = MPU_REGION_NUMBER2;
  MPU_InitStruct.Size = MPU_REGION_SIZE_16MB;
  MPU_InitStruct.AccessPermission = MPU_REGION_FULL_ACCESS;
  MPU_InitStruct.DisableExec = MPU_INSTRUCTION_ACCESS_ENABLE;
  MPU_InitStruct.IsCacheable = MPU_ACCESS_CACHEABLE;

  HAL_MPU_ConfigRegion(&MPU_InitStruct);

  /** Initializes and configures the Region and the memory to be protected
  */
  MPU_InitStruct.Number = MPU_REGION_NUMBER3;
  MPU_InitStruct.Size = MPU_REGION_SIZE_1MB;
  MPU_InitStruct.IsBufferable = MPU_ACCESS_BUFFERABLE;

  HAL_MPU_ConfigRegion(&MPU_InitStruct);
  /* Enables the MPU */
  HAL_MPU_Enable(MPU_PRIVILEGED_DEFAULT);

}

void HAL_TIM_PeriodElapsedCallback(TIM_HandleTypeDef *htim)
{
  if (htim->Instance == TIM6) {
    HAL_IncTick();
  }
}

void Error_Handler(void)
{
  __disable_irq();
  while (1)
  {
  }
}
